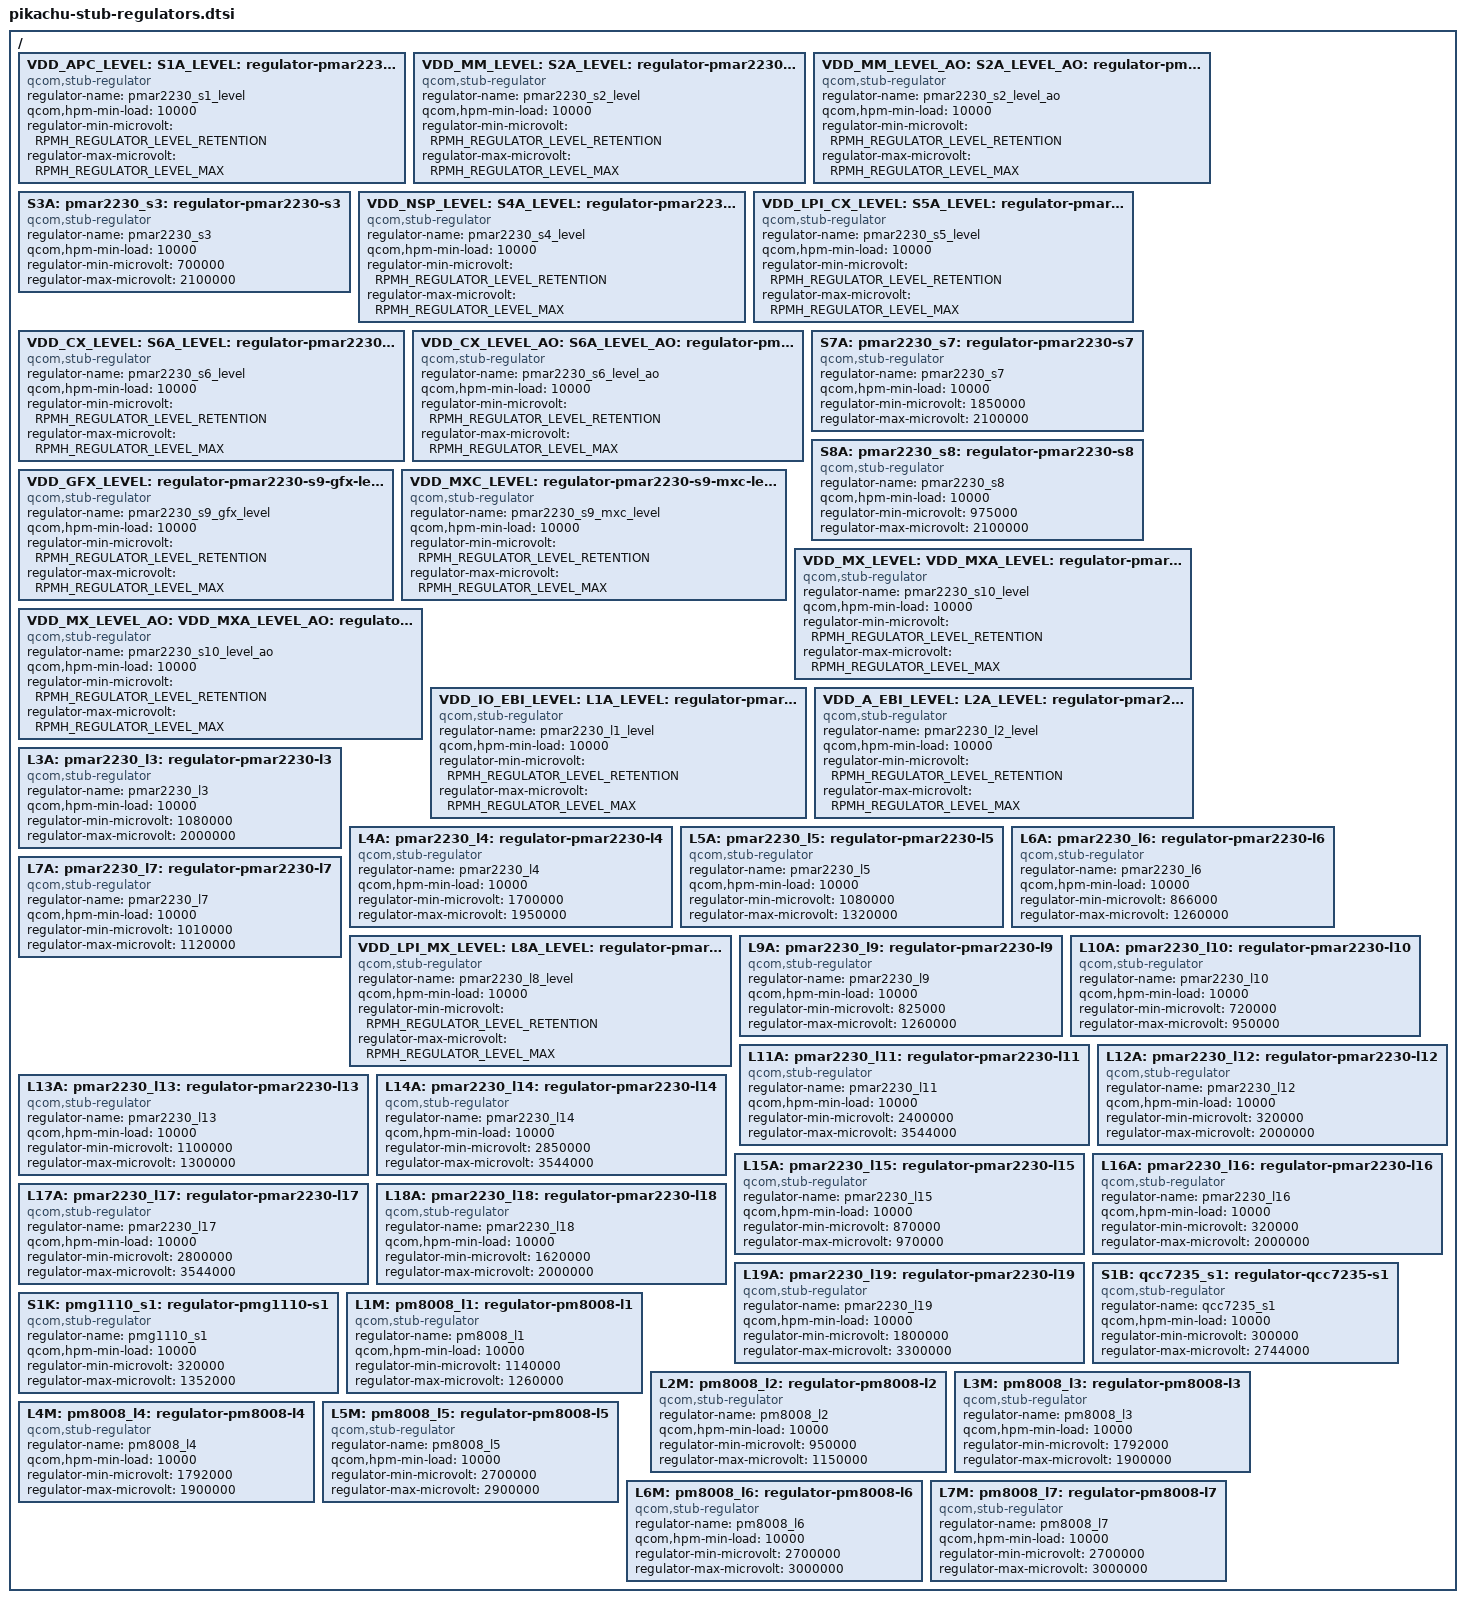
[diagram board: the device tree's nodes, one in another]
// SPDX-License-Identifier: BSD-3-Clause
/*
 * Copyright (c) Qualcomm Technologies, Inc. and/or its subsidiaries.
 */

#include <dt-bindings/regulator/qcom,rpmh-regulator-levels.h>

/ {
	VDD_APC_LEVEL:
	S1A_LEVEL:
	pmar2230_s1_level: regulator-pmar2230-s1-level {
		compatible = "qcom,stub-regulator";
		regulator-name = "pmar2230_s1_level";
		qcom,hpm-min-load = <10000>;
		regulator-min-microvolt =
			<RPMH_REGULATOR_LEVEL_RETENTION>;
		regulator-max-microvolt = <RPMH_REGULATOR_LEVEL_MAX>;
	};

	VDD_MM_LEVEL:
	S2A_LEVEL:
	pmar2230_s2_level: regulator-pmar2230-s2-level {
		compatible = "qcom,stub-regulator";
		regulator-name = "pmar2230_s2_level";
		qcom,hpm-min-load = <10000>;
		regulator-min-microvolt =
			<RPMH_REGULATOR_LEVEL_RETENTION>;
		regulator-max-microvolt = <RPMH_REGULATOR_LEVEL_MAX>;
	};

	VDD_MM_LEVEL_AO:
	S2A_LEVEL_AO:
	pmar2230_s2_level_ao: regulator-pmar2230-s2-level-ao {
		compatible = "qcom,stub-regulator";
		regulator-name = "pmar2230_s2_level_ao";
		qcom,hpm-min-load = <10000>;
		regulator-min-microvolt =
			<RPMH_REGULATOR_LEVEL_RETENTION>;
		regulator-max-microvolt = <RPMH_REGULATOR_LEVEL_MAX>;
	};

	S3A:
	pmar2230_s3: regulator-pmar2230-s3 {
		compatible = "qcom,stub-regulator";
		regulator-name = "pmar2230_s3";
		qcom,hpm-min-load = <10000>;
		regulator-min-microvolt = <700000>;
		regulator-max-microvolt = <2100000>;
	};

	VDD_NSP_LEVEL:
	S4A_LEVEL:
	pmar2230_s4_level: regulator-pmar2230-s4-level {
		compatible = "qcom,stub-regulator";
		regulator-name = "pmar2230_s4_level";
		qcom,hpm-min-load = <10000>;
		regulator-min-microvolt =
			<RPMH_REGULATOR_LEVEL_RETENTION>;
		regulator-max-microvolt = <RPMH_REGULATOR_LEVEL_MAX>;
	};

	VDD_LPI_CX_LEVEL:
	S5A_LEVEL:
	pmar2230_s5_level: regulator-pmar2230-s5-level {
		compatible = "qcom,stub-regulator";
		regulator-name = "pmar2230_s5_level";
		qcom,hpm-min-load = <10000>;
		regulator-min-microvolt =
			<RPMH_REGULATOR_LEVEL_RETENTION>;
		regulator-max-microvolt = <RPMH_REGULATOR_LEVEL_MAX>;
	};

	VDD_CX_LEVEL:
	S6A_LEVEL:
	pmar2230_s6_level: regulator-pmar2230-s6-level {
		compatible = "qcom,stub-regulator";
		regulator-name = "pmar2230_s6_level";
		qcom,hpm-min-load = <10000>;
		regulator-min-microvolt =
			<RPMH_REGULATOR_LEVEL_RETENTION>;
		regulator-max-microvolt = <RPMH_REGULATOR_LEVEL_MAX>;
	};

	VDD_CX_LEVEL_AO:
	S6A_LEVEL_AO:
	pmar2230_s6_level_ao: regulator-pmar2230-s6-level-ao {
		compatible = "qcom,stub-regulator";
		regulator-name = "pmar2230_s6_level_ao";
		qcom,hpm-min-load = <10000>;
		regulator-min-microvolt =
			<RPMH_REGULATOR_LEVEL_RETENTION>;
		regulator-max-microvolt = <RPMH_REGULATOR_LEVEL_MAX>;
	};

	S7A:
	pmar2230_s7: regulator-pmar2230-s7 {
		compatible = "qcom,stub-regulator";
		regulator-name = "pmar2230_s7";
		qcom,hpm-min-load = <10000>;
		regulator-min-microvolt = <1850000>;
		regulator-max-microvolt = <2100000>;
	};

	S8A:
	pmar2230_s8: regulator-pmar2230-s8 {
		compatible = "qcom,stub-regulator";
		regulator-name = "pmar2230_s8";
		qcom,hpm-min-load = <10000>;
		regulator-min-microvolt = <975000>;
		regulator-max-microvolt = <2100000>;
	};

	VDD_GFX_LEVEL:
	regulator-pmar2230-s9-gfx-level {
		compatible = "qcom,stub-regulator";
		regulator-name = "pmar2230_s9_gfx_level";
		qcom,hpm-min-load = <10000>;
		regulator-min-microvolt =
			<RPMH_REGULATOR_LEVEL_RETENTION>;
		regulator-max-microvolt = <RPMH_REGULATOR_LEVEL_MAX>;
	};

	VDD_MXC_LEVEL:
	regulator-pmar2230-s9-mxc-level {
		compatible = "qcom,stub-regulator";
		regulator-name = "pmar2230_s9_mxc_level";
		qcom,hpm-min-load = <10000>;
		regulator-min-microvolt =
			<RPMH_REGULATOR_LEVEL_RETENTION>;
		regulator-max-microvolt = <RPMH_REGULATOR_LEVEL_MAX>;
	};

	VDD_MX_LEVEL:
	VDD_MXA_LEVEL:
	S10A_LEVEL:
	pmar2230_s10_level: regulator-pmar2230-s10-level {
		compatible = "qcom,stub-regulator";
		regulator-name = "pmar2230_s10_level";
		qcom,hpm-min-load = <10000>;
		regulator-min-microvolt =
			<RPMH_REGULATOR_LEVEL_RETENTION>;
		regulator-max-microvolt = <RPMH_REGULATOR_LEVEL_MAX>;
	};

	VDD_MX_LEVEL_AO:
	VDD_MXA_LEVEL_AO:
	S10A_LEVEL_AO:
	pmar2230_s10_level_ao: regulator-pmar2230-s10-level-ao {
		compatible = "qcom,stub-regulator";
		regulator-name = "pmar2230_s10_level_ao";
		qcom,hpm-min-load = <10000>;
		regulator-min-microvolt =
			<RPMH_REGULATOR_LEVEL_RETENTION>;
		regulator-max-microvolt = <RPMH_REGULATOR_LEVEL_MAX>;
	};

	VDD_IO_EBI_LEVEL:
	L1A_LEVEL:
	pmar2230_l1_level: regulator-pmar2230-l1-level {
		compatible = "qcom,stub-regulator";
		regulator-name = "pmar2230_l1_level";
		qcom,hpm-min-load = <10000>;
		regulator-min-microvolt =
			<RPMH_REGULATOR_LEVEL_RETENTION>;
		regulator-max-microvolt = <RPMH_REGULATOR_LEVEL_MAX>;
	};

	VDD_A_EBI_LEVEL:
	L2A_LEVEL:
	pmar2230_l2_level: regulator-pmar2230-l2-level {
		compatible = "qcom,stub-regulator";
		regulator-name = "pmar2230_l2_level";
		qcom,hpm-min-load = <10000>;
		regulator-min-microvolt =
			<RPMH_REGULATOR_LEVEL_RETENTION>;
		regulator-max-microvolt = <RPMH_REGULATOR_LEVEL_MAX>;
	};

	L3A:
	pmar2230_l3: regulator-pmar2230-l3 {
		compatible = "qcom,stub-regulator";
		regulator-name = "pmar2230_l3";
		qcom,hpm-min-load = <10000>;
		regulator-min-microvolt = <1080000>;
		regulator-max-microvolt = <2000000>;
	};

	L4A:
	pmar2230_l4: regulator-pmar2230-l4 {
		compatible = "qcom,stub-regulator";
		regulator-name = "pmar2230_l4";
		qcom,hpm-min-load = <10000>;
		regulator-min-microvolt = <1700000>;
		regulator-max-microvolt = <1950000>;
	};

	L5A:
	pmar2230_l5: regulator-pmar2230-l5 {
		compatible = "qcom,stub-regulator";
		regulator-name = "pmar2230_l5";
		qcom,hpm-min-load = <10000>;
		regulator-min-microvolt = <1080000>;
		regulator-max-microvolt = <1320000>;
	};

	L6A:
	pmar2230_l6: regulator-pmar2230-l6 {
		compatible = "qcom,stub-regulator";
		regulator-name = "pmar2230_l6";
		qcom,hpm-min-load = <10000>;
		regulator-min-microvolt = <866000>;
		regulator-max-microvolt = <1260000>;
	};

	L7A:
	pmar2230_l7: regulator-pmar2230-l7 {
		compatible = "qcom,stub-regulator";
		regulator-name = "pmar2230_l7";
		qcom,hpm-min-load = <10000>;
		regulator-min-microvolt = <1010000>;
		regulator-max-microvolt = <1120000>;
	};

	VDD_LPI_MX_LEVEL:
	L8A_LEVEL:
	pmar2230_l8_level: regulator-pmar2230-l8-level {
		compatible = "qcom,stub-regulator";
		regulator-name = "pmar2230_l8_level";
		qcom,hpm-min-load = <10000>;
		regulator-min-microvolt =
			<RPMH_REGULATOR_LEVEL_RETENTION>;
		regulator-max-microvolt = <RPMH_REGULATOR_LEVEL_MAX>;
	};

	L9A:
	pmar2230_l9: regulator-pmar2230-l9 {
		compatible = "qcom,stub-regulator";
		regulator-name = "pmar2230_l9";
		qcom,hpm-min-load = <10000>;
		regulator-min-microvolt = <825000>;
		regulator-max-microvolt = <1260000>;
	};

	L10A:
	pmar2230_l10: regulator-pmar2230-l10 {
		compatible = "qcom,stub-regulator";
		regulator-name = "pmar2230_l10";
		qcom,hpm-min-load = <10000>;
		regulator-min-microvolt = <720000>;
		regulator-max-microvolt = <950000>;
	};

	L11A:
	pmar2230_l11: regulator-pmar2230-l11 {
		compatible = "qcom,stub-regulator";
		regulator-name = "pmar2230_l11";
		qcom,hpm-min-load = <10000>;
		regulator-min-microvolt = <2400000>;
		regulator-max-microvolt = <3544000>;
	};

	L12A:
	pmar2230_l12: regulator-pmar2230-l12 {
		compatible = "qcom,stub-regulator";
		regulator-name = "pmar2230_l12";
		qcom,hpm-min-load = <10000>;
		regulator-min-microvolt = <320000>;
		regulator-max-microvolt = <2000000>;
	};

	L13A:
	pmar2230_l13: regulator-pmar2230-l13 {
		compatible = "qcom,stub-regulator";
		regulator-name = "pmar2230_l13";
		qcom,hpm-min-load = <10000>;
		regulator-min-microvolt = <1100000>;
		regulator-max-microvolt = <1300000>;
	};

	L14A:
	pmar2230_l14: regulator-pmar2230-l14 {
		compatible = "qcom,stub-regulator";
		regulator-name = "pmar2230_l14";
		qcom,hpm-min-load = <10000>;
		regulator-min-microvolt = <2850000>;
		regulator-max-microvolt = <3544000>;
	};

	L15A:
	pmar2230_l15: regulator-pmar2230-l15 {
		compatible = "qcom,stub-regulator";
		regulator-name = "pmar2230_l15";
		qcom,hpm-min-load = <10000>;
		regulator-min-microvolt = <870000>;
		regulator-max-microvolt = <970000>;
	};

	L16A:
	pmar2230_l16: regulator-pmar2230-l16 {
		compatible = "qcom,stub-regulator";
		regulator-name = "pmar2230_l16";
		qcom,hpm-min-load = <10000>;
		regulator-min-microvolt = <320000>;
		regulator-max-microvolt = <2000000>;
	};

	L17A:
	pmar2230_l17: regulator-pmar2230-l17 {
		compatible = "qcom,stub-regulator";
		regulator-name = "pmar2230_l17";
		qcom,hpm-min-load = <10000>;
		regulator-min-microvolt = <2800000>;
		regulator-max-microvolt = <3544000>;
	};

	L18A:
	pmar2230_l18: regulator-pmar2230-l18 {
		compatible = "qcom,stub-regulator";
		regulator-name = "pmar2230_l18";
		qcom,hpm-min-load = <10000>;
		regulator-min-microvolt = <1620000>;
		regulator-max-microvolt = <2000000>;
	};

	L19A:
	pmar2230_l19: regulator-pmar2230-l19 {
		compatible = "qcom,stub-regulator";
		regulator-name = "pmar2230_l19";
		qcom,hpm-min-load = <10000>;
		regulator-min-microvolt = <1800000>;
		regulator-max-microvolt = <3300000>;
	};

	S1B:
	qcc7235_s1: regulator-qcc7235-s1 {
		compatible = "qcom,stub-regulator";
		regulator-name = "qcc7235_s1";
		qcom,hpm-min-load = <10000>;
		regulator-min-microvolt = <300000>;
		regulator-max-microvolt = <2744000>;
	};

	S1K:
	pmg1110_s1: regulator-pmg1110-s1 {
		compatible = "qcom,stub-regulator";
		regulator-name = "pmg1110_s1";
		qcom,hpm-min-load = <10000>;
		regulator-min-microvolt = <320000>;
		regulator-max-microvolt = <1352000>;
	};

	L1M:
	pm8008_l1: regulator-pm8008-l1 {
		compatible = "qcom,stub-regulator";
		regulator-name = "pm8008_l1";
		qcom,hpm-min-load = <10000>;
		regulator-min-microvolt = <1140000>;
		regulator-max-microvolt = <1260000>;
	};

	L2M:
	pm8008_l2: regulator-pm8008-l2 {
		compatible = "qcom,stub-regulator";
		regulator-name = "pm8008_l2";
		qcom,hpm-min-load = <10000>;
		regulator-min-microvolt = <950000>;
		regulator-max-microvolt = <1150000>;
	};

	L3M:
	pm8008_l3: regulator-pm8008-l3 {
		compatible = "qcom,stub-regulator";
		regulator-name = "pm8008_l3";
		qcom,hpm-min-load = <10000>;
		regulator-min-microvolt = <1792000>;
		regulator-max-microvolt = <1900000>;
	};

	L4M:
	pm8008_l4: regulator-pm8008-l4 {
		compatible = "qcom,stub-regulator";
		regulator-name = "pm8008_l4";
		qcom,hpm-min-load = <10000>;
		regulator-min-microvolt = <1792000>;
		regulator-max-microvolt = <1900000>;
	};

	L5M:
	pm8008_l5: regulator-pm8008-l5 {
		compatible = "qcom,stub-regulator";
		regulator-name = "pm8008_l5";
		qcom,hpm-min-load = <10000>;
		regulator-min-microvolt = <2700000>;
		regulator-max-microvolt = <2900000>;
	};

	L6M:
	pm8008_l6: regulator-pm8008-l6 {
		compatible = "qcom,stub-regulator";
		regulator-name = "pm8008_l6";
		qcom,hpm-min-load = <10000>;
		regulator-min-microvolt = <2700000>;
		regulator-max-microvolt = <3000000>;
	};

	L7M:
	pm8008_l7: regulator-pm8008-l7 {
		compatible = "qcom,stub-regulator";
		regulator-name = "pm8008_l7";
		qcom,hpm-min-load = <10000>;
		regulator-min-microvolt = <2700000>;
		regulator-max-microvolt = <3000000>;
	};
};
